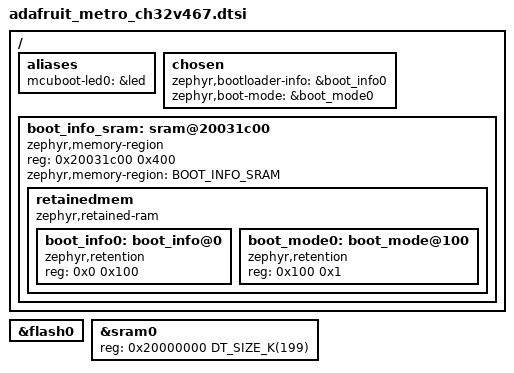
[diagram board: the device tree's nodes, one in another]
/* Board-specific overlay glue for adafruit_metro_ch32v467.
 *
 * Hand-maintained: delete-nodes for partitions that must be replaced,
 * aliases and chosen nodes. The flash partition layout lives in
 * adafruit_metro_ch32v467-partitions.dtsi, which is generated by
 * tools/partition_layout.py --fix and included below.
 */

&flash0 { /delete-node/ partitions; };

/* Status LED for CONFIG_MCUBOOT_INDICATION_LED: the red D13 LED. */
/ {
	aliases {
		mcuboot-led0 = &led;
	};
};

#include "adafruit_metro_ch32v467-partitions.dtsi"

/* Bootloader info shared-data area and boot-mode flag: the last KB of SRAM,
 * which keeps its contents across a system reset. */
&sram0 {
	reg = <0x20000000 DT_SIZE_K(199)>;
};

/ {
	chosen {
		zephyr,bootloader-info = &boot_info0;
		zephyr,boot-mode = &boot_mode0;
	};

	boot_info_sram: sram@20031c00 {
		compatible = "zephyr,memory-region", "mmio-sram";
		reg = <0x20031c00 0x400>;
		zephyr,memory-region = "BOOT_INFO_SRAM";
		status = "okay";

		retainedmem {
			compatible = "zephyr,retained-ram";
			status = "okay";
			#address-cells = <1>;
			#size-cells = <1>;

			boot_info0: boot_info@0 {
				compatible = "zephyr,retention";
				status = "okay";
				reg = <0x0 0x100>;
			};

			boot_mode0: boot_mode@100 {
				compatible = "zephyr,retention";
				status = "okay";
				reg = <0x100 0x1>;
			};
		};
	};
};
